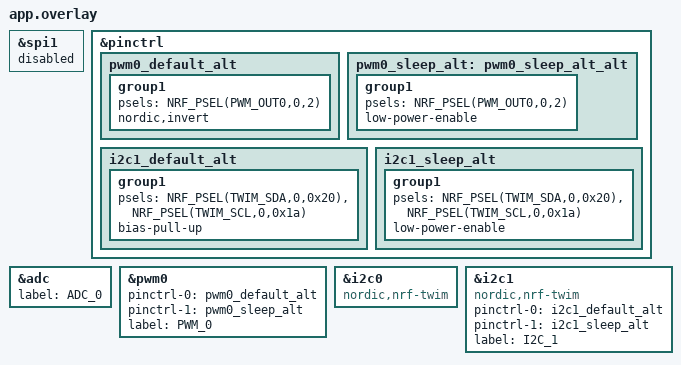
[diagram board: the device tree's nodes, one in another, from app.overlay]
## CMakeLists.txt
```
# SPDX-License-Identifier: Apache-2.0

cmake_minimum_required(VERSION 3.13.1)
find_package(Zephyr REQUIRED HINTS $ENV{ZEPHYR_BASE})
project(peripheral)

target_sources(app PRIVATE
  src/main.c
  src/matrix.c
  src/pwm.c
  src/adc.c
  src/mydevice.c
)
```

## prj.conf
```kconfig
# Incresed stack due to settings API usage
CONFIG_SYSTEM_WORKQUEUE_STACK_SIZE=2048

CONFIG_BT=y
CONFIG_BT_DEBUG_LOG=y
# Security manager protocol support for pairing
CONFIG_BT_SMP=y
# used to sign authenticated data
CONFIG_BT_SIGNING=y
# select peripheral role
CONFIG_BT_PERIPHERAL=y
# enable GATT device information service
CONFIG_BT_DIS=n
# number of buffers available for GATT writing
CONFIG_BT_ATT_PREPARE_COUNT=5
# enable battery service
#CONFIG_BT_BAS=y
# enable Heartrate service
#CONFIG_BT_HRS=y
# enables local privacy feature support ?
CONFIG_BT_PRIVACY=y
# name that appears when browsing
CONFIG_BT_DEVICE_NAME="Andrew Brady's Microbit"
# https://specificationrefs.bluetooth.com/assigned-values/Appearance%20Values.pdf
# 833 = 0x341 = Heartrate belt
#CONFIG_BT_DEVICE_APPEARANCE=833
# 0x4c0 = generic control device = 1216
CONFIG_BT_DEVICE_APPEARANCE=1216
# disable updating of device name to prevent use of generic name
# enable run-time changing of device name
CONFIG_BT_DEVICE_NAME_DYNAMIC=n
CONFIG_BT_DEVICE_NAME_MAX=65

CONFIG_BT_KEYS_OVERWRITE_OLDEST=y
CONFIG_BT_SETTINGS=n
CONFIG_FLASH=y
CONFIG_FLASH_PAGE_LAYOUT=y
CONFIG_FLASH_MAP=y
CONFIG_NVS=y
CONFIG_SETTINGS=y

CONFIG_I2C=y
CONFIG_SENSOR=y
CONFIG_LIS2DH=y
CONFIG_STDOUT_CONSOLE=y
CONFIG_CBPRINTF_FP_SUPPORT=y

CONFIG_ADC=y
CONFIG_PWM=y
```

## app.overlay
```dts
&spi1 {
    status = "disabled";
};
&pinctrl {
    pwm0_default_alt: pwm0_default_alt {
        group1  {
            psels = <NRF_PSEL(PWM_OUT0,0,2)>;
            nordic,invert;
        };
    };
    pwm0_sleep_alt: pwm0_sleep_alt_alt {
        group1  {
            psels = <NRF_PSEL(PWM_OUT0,0,2)>;
            low-power-enable;
        };
    };
    i2c1_default_alt: i2c1_default_alt {
        group1 {
            psels = <NRF_PSEL(TWIM_SDA,0,0x20)>,
                    <NRF_PSEL(TWIM_SCL,0,0x1a)>;
            bias-pull-up;
        };
    };
    i2c1_sleep_alt: i2c1_sleep_alt {
        group1 {
            psels = <NRF_PSEL(TWIM_SDA,0,0x20)>,
                    <NRF_PSEL(TWIM_SCL,0,0x1a)>;
            low-power-enable;
        };
    };
};
&adc {
        status = "okay";
    label = "ADC_0";
    
};
&pwm0 {
    status = "okay";
    //ch0-pin = <3>; // P0.3 is labelled RING1 on the microbit. (connected to pin 1 in breakout board)
    pinctrl-0 = <&pwm0_default_alt>;
    pinctrl-1 = <&pwm0_sleep_alt>;
    pinctrl-names = "default", "sleep";

    label="PWM_0";
};

&i2c0 {
    status = "okay";
    compatible = "nordic,nrf-twim";

};
&i2c1 {
    compatible = "nordic,nrf-twim";
    status = "okay";
    pinctrl-0 = <&i2c1_default_alt>;
    pinctrl-1 = <&i2c1_sleep_alt>;
    pinctrl-names = "default", "sleep";
    label = "I2C_1";

};
```

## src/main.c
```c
/* main.c - Application main entry point */

/* Based on an example from Zephyr toolkit, modified by frank duignan
 * SPDX-License-Identifier: Apache-2.0
 */
/* This example advertises three services:
 * 0x1800 Generic ACCESS (GAP)
 * 0x1801 Generic Attribute (GATT - this is part of the software device and is not used nor is it apparently removable see https://devzone.nordicsemi.com/f/nordic-q-a/15076/removing-the-generic-attribute-0x1801-primary-service-if-the-service-changed-characteristic-is-not-present
 * And a custom service 1-2-3-4-0 
 * This custom service contains a custom characteristic called char_value
 */
#include <zephyr/types.h>
#include <stddef.h>
#include <string.h>
#include <errno.h>
#include <zephyr/sys/printk.h>
#include <zephyr/sys/byteorder.h>
#include <zephyr/zephyr.h>

#include <zephyr/settings/settings.h>

#include <zephyr/bluetooth/bluetooth.h>
#include <zephyr/bluetooth/hci.h>
#include <zephyr/bluetooth/conn.h>
#include <zephyr/bluetooth/uuid.h>
#include <zephyr/bluetooth/gatt.h>
#include <zephyr/device.h>
#include <zephyr/drivers/sensor.h>
#include <stdio.h>
#include "matrix.h"
#include "adc.h"
#include "pwm.h"
#include "mydevice.h"

// ********************[ Start of Temperature characteristic ]**************************************
#define BT_UUID_mytemperature_ID  	   BT_UUID_128_ENCODE(1, 2, 3, 4, (uint64_t)0x8001)
static struct bt_uuid_128 mytemperature_id=BT_UUID_INIT_128(BT_UUID_mytemperature_ID); // the 128 bit UUID for this gatt value
uint32_t mytemperature;
static ssize_t read_mytemperature(struct bt_conn *conn, const struct bt_gatt_attr *attr, void *buf, uint16_t len, uint16_t offset);
static ssize_t read_mytemperature(struct bt_conn *conn, const struct bt_gatt_attr *attr, void *buf, uint16_t len, uint16_t offset)
// Reading temperature
{
	printk("Got an mytemperature read %d\n",mytemperature);
	const char *value = (const char *)&mytemperature;
	return bt_gatt_attr_read(conn, attr, buf, len, offset, value, sizeof(mytemperature)); // pass the value back up through the BLE stack
	return 0;
}

// Callback that is activated when the characteristic is written by central
static ssize_t write_mytemperature(struct bt_conn *conn, const struct bt_gatt_attr *attr, const void *buf, uint16_t len, uint16_t offset, uint8_t flags)
{
	uint8_t *value = attr->user_data;
	printk("Got an mytemperature write\n");
	memcpy(value, buf, sizeof(mytemperature)); // copy the incoming value in the memory occupied by our characateristic variable    
	return len;
}

// Arguments to BT_GATT_CHARACTERISTIC = _uuid, _props, _perm, _read, _write, _value
#define BT_GATT_mytemperature BT_GATT_CHARACTERISTIC(&mytemperature_id.uuid, BT_GATT_CHRC_READ | BT_GATT_CHRC_WRITE, BT_GATT_PERM_READ | BT_GATT_PERM_WRITE , read_mytemperature, write_mytemperature, &mytemperature)
// ********************[ End of Temperature characteristic ]**************************************

// ********************[ Start of Pressure characteristic ]**************************************
#define BT_UUID_mypressure_ID  	   BT_UUID_128_ENCODE(1, 2, 3, 4, (uint64_t)0x8002)
static struct bt_uuid_128 mypressure_id=BT_UUID_INIT_128(BT_UUID_mypressure_ID); // the 128 bit UUID for this gatt value
uint32_t mypressure;
static ssize_t read_mypressure(struct bt_conn *conn, const struct bt_gatt_attr *attr, void *buf, uint16_t len, uint16_t offset);
static ssize_t read_mypressure(struct bt_conn *conn, const struct bt_gatt_attr *attr, void *buf, uint16_t len, uint16_t offset)
//Reading pressure
{
	printk("Got an mypressure read %d\n",mypressure);
	const char *value = (const char *)&mypressure;
	return bt_gatt_attr_read(conn, attr, buf, len, offset, value, sizeof(mypressure)); // pass the value back up through the BLE stack
	return 0;
}

// Callback that is activated when the characteristic is written by central
static ssize_t write_mypressure(struct bt_conn *conn, const struct bt_gatt_attr *attr, const void *buf, uint16_t len, uint16_t offset, uint8_t flags)
{
	uint8_t *value = attr->user_data;
	printk("Got an mypressure write\n");
	memcpy(value, buf, sizeof(mypressure)); // copy the incoming value in the memory occupied by our characateristic variable    
	return len;
}

// Arguments to BT_GATT_CHARACTERISTIC = _uuid, _props, _perm, _read, _write, _value
#define BT_GATT_mypressure BT_GATT_CHARACTERISTIC(&mypressure_id.uuid, BT_GATT_CHRC_READ | BT_GATT_CHRC_WRITE, BT_GATT_PERM_READ | BT_GATT_PERM_WRITE , read_mypressure, write_mypressure, &mypressure)
// ********************[ End of Pressure characteristic ]**************************************

// ********************[ Service definition ]********************
#define BT_UUID_mytemperature_SERVICE_VAL BT_UUID_128_ENCODE(1, 2, 3, 4, (uint64_t)0x8000)
static struct bt_uuid_128 my_mytemperature_service_uuid = BT_UUID_INIT_128( BT_UUID_mytemperature_SERVICE_VAL);
    
BT_GATT_SERVICE_DEFINE(my_mytemperature_service_svc,
    BT_GATT_PRIMARY_SERVICE(&my_mytemperature_service_uuid),
    BT_GATT_mytemperature,
    BT_GATT_mypressure
);


#define BT_UUID_CUSTOM_SERVICE_VAL BT_UUID_128_ENCODE(1, 2, 3, 4, (uint64_t)0)
static struct bt_uuid_128 my_service_uuid = BT_UUID_INIT_128( BT_UUID_CUSTOM_SERVICE_VAL);
static struct bt_uuid_128 char_id=BT_UUID_INIT_128(BT_UUID_128_ENCODE(1, 2, 3, 4, (uint64_t)5)); // the 128 bit UUID for this gatt value
uint32_t char_value; // the gatt characateristic value that is being shared over BLE	
static ssize_t read_char(struct bt_conn *conn, const struct bt_gatt_attr *attr, void *buf, uint16_t len, uint16_t offset);
static ssize_t write_char(struct bt_conn *conn, const struct bt_gatt_attr *attr, const void *buf, uint16_t len, uint16_t offset, uint8_t flags);
static void subscribe_changed(const struct bt_gatt_attr *attr,uint16_t value);
volatile int Subscribed = 0;

// bt_data is an array of data structures used in advertising.
static const struct bt_data ad[] = {
	BT_DATA_BYTES(BT_DATA_FLAGS, (BT_LE_AD_GENERAL | BT_LE_AD_NO_BREDR)), /* specify BLE advertising flags = discoverable, BR/EDR not supported (BLE only) */
	BT_DATA_BYTES(BT_DATA_UUID128_ALL, BT_UUID_CUSTOM_SERVICE_VAL /* A 128 Service UUID for the our custom service follows */),
};
	
	
BT_GATT_SERVICE_DEFINE(my_service_svc,
	BT_GATT_PRIMARY_SERVICE(&my_service_uuid),
		BT_GATT_CHARACTERISTIC(&char_id.uuid,		
		BT_GATT_CHRC_READ | BT_GATT_CHRC_WRITE |  BT_GATT_CHRC_NOTIFY,
		BT_GATT_PERM_READ | BT_GATT_PERM_WRITE,
		read_char, write_char, &char_value),
        BT_GATT_CCC(subscribe_changed,BT_GATT_PERM_READ | BT_GATT_PERM_WRITE)
);

struct bt_conn *active_conn=NULL; // use this to maintain a reference to the connection with the central device (if any)

// Callback that is activated when the characteristic is read by central
static ssize_t read_char(struct bt_conn *conn, const struct bt_gatt_attr *attr, void *buf, uint16_t len, uint16_t offset)
{
	printf("Got a read %p\n",attr);
	// Could use 'const char *value =  attr->user_data' also here if there is the char value is being maintained with the BLE STACK
	const char *value = (const char *)&char_value; // point at the value in memory
	return bt_gatt_attr_read(conn, attr, buf, len, offset, value, sizeof(char_value)); // pass the value back up through the BLE stack
}

// Callback that is activated when the characteristic is written by central
static ssize_t write_char(struct bt_conn *conn, const struct bt_gatt_attr *attr, const void *buf, uint16_t len, uint16_t offset, uint8_t flags)
{
	uint8_t *value = attr->user_data;
	printf("Got a write\n");
    len = sizeof(value); // don't want to write past the end of "value" so determine appropriate size here
	memcpy(value, buf, len); // copy the incoming value in the memory occupied by our characateristic variable
	return len;
}

// Callback that is activated when a connection with a central device is established
static void connected(struct bt_conn *conn, uint8_t err)
{
	if (err) {
		printk("Connection failed (err 0x%02x)\n", err);
	} else {
		printk("Connected\n");
		active_conn = conn;
	}
}

// Callback that is activated when a connection with a central device is taken down
static void disconnected(struct bt_conn *conn, uint8_t reason)
{
	printk("Disconnected (reason 0x%02x)\n", reason);
	active_conn = NULL;
}

// Callback that is activated when a connection with a central device subscribed
static void subscribe_changed(const struct bt_gatt_attr *attr, uint16_t value)
{   if (value==BT_GATT_CCC_NOTIFY)
    {
       printk("Subscribed\n");
       Subscribed = 1;
    }
    else
    {
        printk("Not Subscribed\n");
        Subscribed = 0;
    }
}

// structure used to pass connection callback handlers to the BLE stack
static struct bt_conn_cb conn_callbacks = {
	.connected = connected,
	.disconnected = disconnected,
};

// This is called when the BLE stack has finished initializing
static void bt_ready(void)
{
	int err;
	printk("Bluetooth initialized\n");

// start advertising see https://developer.nordicsemi.com/nRF_Connect_SDK/doc/latest/zephyr/reference/bluetooth/gap.html

// Start BLE advertising using the ad array 
	err = bt_le_adv_start(BT_LE_ADV_CONN_NAME, ad, ARRAY_SIZE(ad), NULL, 0);
	if (err) {
		printk("Advertising failed to start (err %d)\n", err);
		return;
	}
	printk("Advertising successfully started\n");
}

void main(void)
{
	int err;
	err = device_begin();
	//error handling
	if(err)
	{
		printk("Error starting I2C1 bus %d\n",err);
	}
	else
	{
		printk("I2C1 success\n");
	}
	uint8_t test;
	err = mydevice_readRegister(9, &test);
	printk("Test Number %d\n",test);
	if(err)
	{
		printk("Error reading device %d\n",err);
	}
	else
	{
		printk("Device read ok\n");
	}
	err = adc_begin();
	err = pwm_begin();
	matrix_begin();
	matrix_all_off();
	err = bt_enable(NULL);
	if (err) {
		printk("Bluetooth init failed (err %d)\n", err);
		return;
	}

	//printing readings
	bt_ready();
	bt_conn_cb_register(&conn_callbacks);
	printk("Zephyr Microbit V2 minimal BLE example! %s\n", CONFIG_BOARD);			
	while (1) {
        printf("Temp = %d\n",mydevice_readTemperature());
		printf("Pressure = %d\n",mydevice_readPressure());
		
		mytemperature = mydevice_readTemperature();
		mypressure = mydevice_readPressure();
		k_sleep(K_SECONDS(1));
		if(char_value == 0)
		{
			matrix_all_off();
		}
		else
		{
			matrix_put_pattern(0x1f,0);
		}
		char_value++;
		
		if (active_conn)
		{
            if (Subscribed)
            {
                bt_gatt_notify(active_conn,&my_service_svc.attrs[2], &char_value,sizeof(char_value));

            }
        }
	}
	
}
```

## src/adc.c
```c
#include <stdint.h>
#include <zephyr/sys/printk.h>
#include <zephyr/device.h>
#include <zephyr/drivers/adc.h>
#include <stdio.h>
#include "adc.h"
/*
 * The internal voltage reference is 0.6V
 * The permissable gains are 1/6, 1/5, 1/4, 1/3, 1/2, 1, 2 and 4
 * If a gain of 1/5 is selected then the ADC range becomes 0 to 3V
 */
static const struct device *adc;
// Will read from analog input on P0.2 which is RING 0 on the microbit v2
#define ADC_PORT_BIT 2
#define ADC_RANGE 3.0
struct adc_channel_cfg channel_cfg = {
		/* gain of 1/5 */
		.gain = ADC_GAIN_1_5,
		/* 0.6V reference */
		.reference = ADC_REF_INTERNAL,
		/* sample and hold time of 3us is the default (0 setting) on the NRF52833 */
		.acquisition_time = ADC_ACQ_TIME_DEFAULT,
		/* Channel 0 */
		.channel_id = 1,
		/* AIN0 is specified by setting input_positive to 0+1 i.e. an offset of 1  */
		/* This is as a result of the way the PSELP and PSELN registers work in the NRF52 series of devices */
		.input_positive = 2,
		/* Using single ended conversions */
        .differential = 0
};
static int16_t channel_0_data;  // This will hold the adc result

struct adc_sequence sequence = {        
		/* This is a bitmask that tells the driver which channels to convert : bit n = 1 for channel n */		
		.channels    = (1 << 1),
		/* Where will the data be stored (could be an array if there are multiple channels to convert */
		.buffer      = &channel_0_data,
		/* buffer size in bytes, not number of samples */
		.buffer_size = sizeof(channel_0_data),
		/* 12 bit resolution */
		.resolution  = 12,
		/* nulls for the rest of the fields */
		.options = NULL,
		.calibrate = 0,
		.oversampling = 0,        
};
int adc_readDigital()
{
	int ret;
	ret = adc_read(adc, &sequence);	
	return channel_0_data;
}
int adc_begin()
{
	int ret;
	// get a pointer to the ADC device structure
	adc=DEVICE_DT_GET(DT_NODELABEL(adc));
	if (adc == NULL)
	{
		printk("Error acquiring ADC \n");
		return -1;
	}
	ret = adc_channel_setup(adc, &channel_cfg);
	if (ret < 0)
	{
		printk("Error configuring ADC channel 0\n");
		return -2;
	}		
	return 0;
}
double adc_readVoltage()
{
	double returnValue = adc_readDigital();
	returnValue = (returnValue * ADC_RANGE) / 4095.0;
	return returnValue;
}
```

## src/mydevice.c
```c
#include <zephyr/sys/printk.h>
#include <zephyr/device.h>
#include <zephyr/drivers/gpio.h>
#include <zephyr/drivers/spi.h>
#include <zephyr/drivers/i2c.h>
#include <stdio.h>
#include <stdint.h>
#include "mydevice.h"
static int32_t t_fine;
static uint16_t dig_T1; //calibration for temperature
static int16_t  dig_T2; //calibration for temperature
static int16_t  dig_T3; //calibration for temperature
static uint16_t dig_P1; //calibration for pressure
static int16_t  dig_P2; //calibration for pressure
static int16_t  dig_P3; //calibration for pressure
static int16_t  dig_P4; //calibration for pressure
static int16_t  dig_P5; //calibration for pressure
static int16_t  dig_P6; //calibration for pressure
static int16_t  dig_P7; //calibration for pressure
static int16_t  dig_P8; //calibration for pressure
static int16_t  dig_P9; //calibration for pressure
#define DEVICE_ADDRESS (0x76) //taken from bmp280 data sheet
// "private" functions for use within this module only
int readRegister(uint8_t RegNum, uint8_t *Value);
int writeRegister(uint8_t RegNum, uint8_t Value);
void readCalibrationData();
//static const struct spi_config * cfg;
static const struct device *i2c;
int device_begin()
{
	// Set up the I2C interface
	i2c = device_get_binding("I2C_1");
	if (i2c==NULL)
	{
		printf("Error acquiring i2c1 interface\n");
		return -1;
	}	
	mydevice_readCalibrationData();
	return 0;
}

int32_t mydevice_readPressure() // returns Pressure * 100
{
    mydevice_readTemperature();  //Pressure reading needs the temperature reading to calculate pressure      
    uint8_t PressureMSB,PressureLSB, PressureXLSB;
    mydevice_readRegister(0xF7, &PressureMSB);
    mydevice_readRegister(0xF8, &PressureLSB);
    mydevice_readRegister(0xF9, &PressureXLSB);
    //Convert pressure data bytes to 20-bits within 32 bit integer
    uint32_t adc_P = (((uint32_t)PressureMSB<<12)+((uint32_t)PressureLSB<<4)+((uint32_t)PressureXLSB>>4));
    
    // FROM DATASHEET
    int32_t var1,var2;
    uint32_t p;
    var1 = (((int32_t)t_fine) >> 1) - (int32_t)64000;
    var2 = (((var1 >> 2) * (var1 >> 2)) >> 11) * ((int32_t)dig_P6);
    var2 = var2 + ((var1*((int32_t)dig_P5)) << 1);
    var2 = (var2 >> 2) + (((int32_t)dig_P4) << 16);
    var1 = (((dig_P3 * (((var1 >> 2) * (var1 >> 2)) >> 13)) >> 3) + ((((int32_t)dig_P2)*var1)>>1)) >> 18;
    var1 = ((((32768+var1))*((int32_t)dig_P1)) >> 15);
    if (var1 == 0)
    {
        return 0;
    }
    p = (((uint32_t)(((int32_t)1048576)-adc_P) - (var2 >> 12)))*3125;
    if (p < 0x80000000)
    {
        p = (p << 1) / ((uint32_t)var1);
    }
    else
    {
        p = (p / (uint32_t)var1)*2;
    }
    var1 = (((int32_t)dig_P9) * ((int32_t)(((p >> 3)) >> 13))) >> 12;
    var2 = (((int32_t)(p >> 2)) * ((int32_t) dig_P8)) >> 13;
    p = (uint32_t)((int32_t)p + ((var1 + var2 + dig_P7) >> 4));
    p = p/100;
    return p;    
}

int32_t mydevice_readTemperature() // returns Temperature * 100
{
    int32_t var1,var2,T;
    //function to read the temperature in BMP280, calibrate it and return the value in Celsius
    mydevice_writeRegister (0xF4, 0x2E);// Initializing the write register for temperature
    uint8_t status =0x08;
    //Start the i2c transmission
    while(status &0x08){
        mydevice_readRegister(0xF3, &status);
    }
    //Temperature reading transmitted in 3 parts - MSB, LSB & XLSB
    uint8_t TemperatureMSB,TemperatureLSB, TemperatureXLSB;
    mydevice_readRegister(0xFA, &TemperatureMSB);
    mydevice_readRegister(0xFB, &TemperatureLSB);
    mydevice_readRegister(0xFC, &TemperatureXLSB);
    
    //Convert temperature data bytes to 20-bits within 32 bit integer
    int32_t adc_T = (((long)TemperatureMSB<<16)+((long)TemperatureLSB<<8)+(long)TemperatureXLSB)>>4;
    
    // FROM DATASHEET
    var1 = ((((adc_T >> 3) - ((int32_t)dig_T1 << 1 ))) * ((int32_t) dig_T2)) >> 11;
    var2 = (((((adc_T >> 4) - ((int32_t)dig_T1)) * ((adc_T >> 4) - ((int32_t)dig_T1))) >> 12) * ((int32_t)dig_T3)) >> 14;
    t_fine = var1 + var2; // store to static (private to this module) variable so that pressure routine can access temperature data
    T = (t_fine * 5 + 128) >> 8;
    T = T/100;
    return T;
}

int mydevice_readRegister(uint8_t RegNum, uint8_t *Value)
{
	    //reads a byte from a specific register
    int nack;   
	nack=i2c_reg_read_byte(i2c,DEVICE_ADDRESS,RegNum,Value);
	return nack;
}
int mydevice_writeRegister(uint8_t RegNum, uint8_t Value)
{
	//writes a byte to a specific register
    uint8_t Buffer[2];    
    Buffer[0]= Value;    
    int nack;    
	nack=i2c_reg_write_byte(i2c,DEVICE_ADDRESS,RegNum,Value);
    return nack;
}
void mydevice_readCalibrationData()
{
	uint8_t CalibrationData[26];
    int i;
#define CAL_START 0x88 //Defining the address where the calibration data should start 
    for(i=0;i<26;i++)
    {
        //Read calibration table
        mydevice_readRegister(CAL_START+i, &CalibrationData[i]);
        
    }        
    dig_T1 = ((uint16_t)CalibrationData[1]<<8) + (uint16_t) (CalibrationData[0]);
    dig_T2 = ((uint16_t)CalibrationData[3]<<8) + (uint16_t) (CalibrationData[2]);
    dig_T3 = ((uint16_t)CalibrationData[5]<<8) + (uint16_t) (CalibrationData[4]);
    dig_P1 = ((uint16_t)CalibrationData[7]<<8) + (uint16_t) (CalibrationData[6]);
    dig_P2 = ((uint16_t)CalibrationData[9]<<8) + (uint16_t) (CalibrationData[8]);
    dig_P3 = ((uint16_t)CalibrationData[11]<<8)+ (uint16_t) (CalibrationData[10]);
    dig_P4 = ((uint16_t)CalibrationData[13]<<8)+ (uint16_t) (CalibrationData[12]);
    dig_P5 = ((uint16_t)CalibrationData[15]<<8)+ (uint16_t) (CalibrationData[14]);
    dig_P6 = ((uint16_t)CalibrationData[17]<<8)+ (uint16_t) (CalibrationData[16]);
    dig_P7 = ((uint16_t)CalibrationData[19]<<8)+ (uint16_t) (CalibrationData[18]);
    dig_P8 = ((uint16_t)CalibrationData[21]<<8)+ (uint16_t) (CalibrationData[20]);
    dig_P9 = ((uint16_t)CalibrationData[23]<<8)+  (uint16_t) (CalibrationData[22]);
}
```

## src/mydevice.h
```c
int device_begin(void);

int mydevice_readRegister(uint8_t RegNum, uint8_t *Value);

int mydevice_writeRegister(uint8_t RegNum, uint8_t Value);

int32_t mydevice_readPressure(); // returns Pressure * 100
int32_t mydevice_readTemperature(); // returns Temperature * 100

void mydevice_readCalibrationData(void);
```
